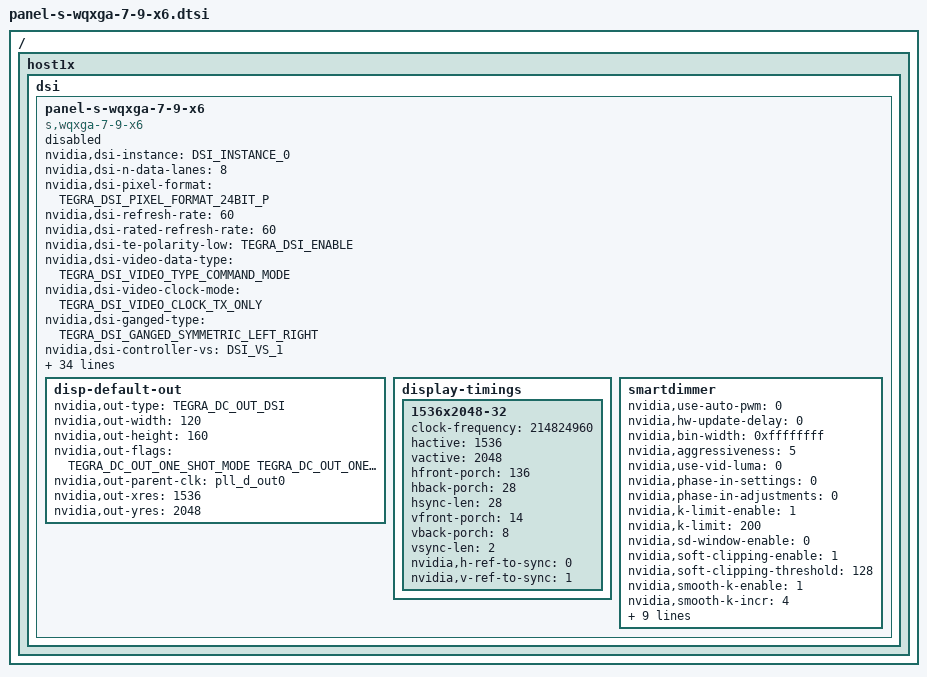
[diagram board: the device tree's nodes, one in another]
/*
 * arch/arm/boot/dts/panel-s-wqxga-7-9-x6.dtsi
 *
 * Copyright (c) 2014-2015, NVIDIA CORPORATION.  All rights reserved.
 *
 * This program is free software; you can redistribute it and/or modify
 * it under the terms of the GNU General Public License as published by
 * the Free Software Foundation; either version 2 of the License, or
 * (at your option) any later version.
 *
 * This program is distributed in the hope that it will be useful, but WITHOUT
 * ANY WARRANTY; without even the implied warranty of MERCHANTABILITY or
 * FITNESS FOR A PARTICULAR PURPOSE.  See the GNU General Public License for
 * more details.
 *
 * You should have received a copy of the GNU General Public License along
 * with this program; if not, write to the Free Software Foundation, Inc.,
 * 51 Franklin Street, Fifth Floor, Boston, MA  02110-1301, USA.
 */
#include <dt-bindings/display/tegra-dc.h>
#include <dt-bindings/display/tegra-panel.h>

/ {
	host1x {
		dsi {
			panel-s-wqxga-7-9-x6 {
				status = "disabled";
				compatible = "s,wqxga-7-9-x6";
				nvidia,dsi-instance = <DSI_INSTANCE_0>;
				nvidia,dsi-n-data-lanes = <8>;
				nvidia,dsi-pixel-format = <TEGRA_DSI_PIXEL_FORMAT_24BIT_P>;
				nvidia,dsi-refresh-rate = <60>;
				nvidia,dsi-rated-refresh-rate = <60>;
				nvidia,dsi-te-polarity-low = <TEGRA_DSI_ENABLE>;
				nvidia,dsi-video-data-type = <TEGRA_DSI_VIDEO_TYPE_COMMAND_MODE>;
				nvidia,dsi-video-clock-mode = <TEGRA_DSI_VIDEO_CLOCK_TX_ONLY>;
				nvidia,dsi-ganged-type = <TEGRA_DSI_GANGED_SYMMETRIC_LEFT_RIGHT>;
				nvidia,dsi-controller-vs = <DSI_VS_1>;
				nvidia,dsi-virtual-channel = <TEGRA_DSI_VIRTUAL_CHANNEL_0>;
				nvidia,dsi-panel-reset = <TEGRA_DSI_ENABLE>;
				nvidia,dsi-power-saving-suspend = <TEGRA_DSI_ENABLE>;
				nvidia,dsi-lp00-pre-panel-wakeup = <TEGRA_DSI_ENABLE>;
				nvidia,dsi-ulpm-not-support = <TEGRA_DSI_ENABLE>;
				nvidia,dsi-suspend-aggr = <DSI_HOST_SUSPEND_LV2>;
				nvidia,dsi-init-cmd =
							/* Long  Packet: <PACKETTYPE[u8] COMMANDID[u8] PAYLOADCOUNT[u16] ECC[u8] PAYLOAD[..] CHECKSUM[u16]> */
							/* Short Packet: <PACKETTYPE[u8] COMMANDID[u8] DATA0[u8] DATA1[u8] ECC[u8]> */
							/* For DSI packets each DT cell is interpreted as u8 not u32 */
							
							<TEGRA_DSI_PACKET_CMD DSI_DCS_WRITE_0_PARAM DSI_DCS_EXIT_SLEEP_MODE DSI_DCS_NO_OP 0x0>,
							<TEGRA_DSI_PACKET_CMD DSI_DCS_WRITE_0_PARAM DSI_DCS_EXIT_SLEEP_MODE DSI_DCS_NO_OP 0x1>,
							<TEGRA_DSI_DELAY_MS 120>,
							<TEGRA_DSI_PACKET_CMD DSI_DCS_WRITE_1_PARAM 0x53 0x2C 0x0>,
							<TEGRA_DSI_PACKET_CMD DSI_DCS_WRITE_1_PARAM 0x53 0x2C 0x1>,
							<TEGRA_DSI_DELAY_MS 20>,
							<TEGRA_DSI_PACKET_CMD DSI_DCS_WRITE_1_PARAM 0x55 0x01 0x0>,
							<TEGRA_DSI_PACKET_CMD DSI_DCS_WRITE_1_PARAM 0x55 0x01 0x1>,
							<TEGRA_DSI_DELAY_MS 20>,
							<TEGRA_DSI_PACKET_CMD DSI_DCS_WRITE_1_PARAM 0x53 0x2C 0x0>,
							<TEGRA_DSI_PACKET_CMD DSI_DCS_WRITE_1_PARAM 0x53 0x2C 0x1>,
							<TEGRA_DSI_DELAY_MS 20>,
							<TEGRA_DSI_PACKET_CMD DSI_DCS_WRITE_0_PARAM DSI_DCS_SET_DISPLAY_ON DSI_DCS_NO_OP 0x0>,
							<TEGRA_DSI_PACKET_CMD DSI_DCS_WRITE_0_PARAM DSI_DCS_SET_DISPLAY_ON DSI_DCS_NO_OP 0x1>,
							<TEGRA_DSI_DELAY_MS 120>;
				nvidia,dsi-n-init-cmd = <15>;
				nvidia,dsi-suspend-cmd =
							<TEGRA_DSI_PACKET_CMD DSI_DCS_WRITE_0_PARAM DSI_DCS_SET_DISPLAY_OFF 0x0 0x0>,
							<TEGRA_DSI_PACKET_CMD DSI_DCS_WRITE_0_PARAM DSI_DCS_SET_DISPLAY_OFF 0x0 0x1>,
							<TEGRA_DSI_DELAY_MS 100>,
							<TEGRA_DSI_PACKET_CMD DSI_DCS_WRITE_0_PARAM DSI_DCS_ENTER_SLEEP_MODE 0x0 0x0>,
							<TEGRA_DSI_PACKET_CMD DSI_DCS_WRITE_0_PARAM DSI_DCS_ENTER_SLEEP_MODE 0x0 0x1>,
							<TEGRA_DSI_DELAY_MS 150>;
				nvidia,dsi-n-suspend-cmd = <6>;
				disp-default-out {
					nvidia,out-type = <TEGRA_DC_OUT_DSI>;
					nvidia,out-width = <120>;
					nvidia,out-height = <160>;
					nvidia,out-flags = <TEGRA_DC_OUT_ONE_SHOT_MODE TEGRA_DC_OUT_ONE_SHOT_LP_MODE>;
					nvidia,out-parent-clk = "pll_d_out0";
					nvidia,out-xres = <1536>;
					nvidia,out-yres = <2048>;
				};
				display-timings {
					1536x2048-32 {
						clock-frequency = <214824960>;
						hactive = <1536>;
						vactive = <2048>;
						hfront-porch = <136>;
						hback-porch = <28>;
						hsync-len = <28>;
						vfront-porch = <14>;
						vback-porch = <8>;
						vsync-len = <2>;
						nvidia,h-ref-to-sync = <0>;
						nvidia,v-ref-to-sync = <1>;
					};
				};
				smartdimmer {
					status = "okay";
					nvidia,use-auto-pwm = <0>;
					nvidia,hw-update-delay = <0>;
					nvidia,bin-width = <0xffffffff>;
					nvidia,aggressiveness = <5>;
					nvidia,use-vid-luma = <0>;
					nvidia,phase-in-settings = <0>;
					nvidia,phase-in-adjustments = <0>;
					nvidia,k-limit-enable = <1>;
					nvidia,k-limit = <200>;
					nvidia,sd-window-enable = <0>;
					nvidia,soft-clipping-enable= <1>;
					nvidia,soft-clipping-threshold = <128>;
					nvidia,smooth-k-enable = <1>;
					nvidia,smooth-k-incr = <4>;
					nvidia,coeff = <5 9 2>;
					nvidia,fc = <0 0>;
					nvidia,blp = <1024 255>;
					nvidia,bltf = <57 65 73 82
						       92 103 114 125
						       138 150 164 178
						       193 208 224 241>;
					nvidia,lut = <255 255 255
						      199 199 199
						      153 153 153
						      116 116 116
						      85 85 85
						      59 59 59
						      36 36 36
						      17 17 17
						      0 0 0>;
					nvidia,use-vpulse2 = <1>;
					nvidia,bl-device-name = "nvidia,tegra124-i2c";
				};
			};
		};
	};
};
